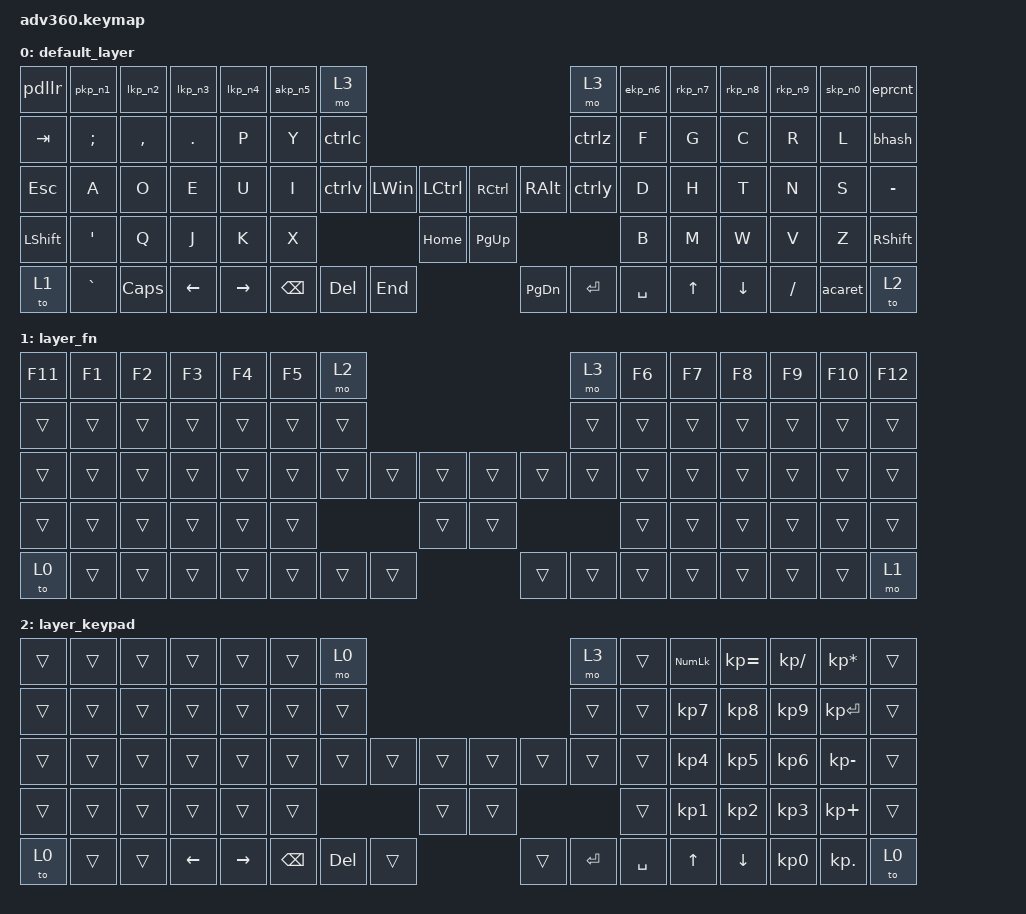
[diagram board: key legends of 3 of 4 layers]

/*
 * Copyright (c) 2020 The ZMK Contributors
 *
 * SPDX-License-Identifier: MIT
 */


/* THIS FILE WAS GENERATED!
 *
 * This file was generated automatically. You may or may not want to
 * edit it directly.
 */

#include <behaviors.dtsi>
#include <dt-bindings/zmk/keys.h>
#include <dt-bindings/zmk/bt.h>
#include <dt-bindings/zmk/rgb.h>
#include <dt-bindings/zmk/backlight.h>

/ {
  behaviors {
    #include "macros.dtsi"

    hm: homerow_mods {
        compatible = "zmk,behavior-hold-tap";
        label = "HOMEROW_MODS";
        #binding-cells = <2>;
        tapping-term-ms = <200>;
        quick_tap_ms = <175>;
        flavor = "tap-preferred";
        bindings = <&kp>, <&kp>;
    };

    pkp_n1: plus_kp_n1 {
        compatible = "zmk,behavior-mod-morph";
        label = "plus_kp_n1";
        #binding-cells = <0>;
        bindings = <&kp PLUS>, <&kp KP_N1>;
        mods = <(MOD_LSFT|MOD_RSFT|MOD_RGUI|MOD_LGUI)>;
    };
    lkp_n2: left_bracket_kp_n2 {
        compatible = "zmk,behavior-mod-morph";
        label = "left_bracket_kp_n2";
        #binding-cells = <0>;
        bindings = <&kp LEFT_BRACKET>, <&kp KP_N2>;
        mods = <(MOD_LSFT|MOD_RSFT|MOD_RGUI|MOD_LGUI)>;
       
    };
    lkp_n3: left_brace_kp_n3 {
        compatible = "zmk,behavior-mod-morph";
        label = "left_brace_kp_n3";
        #binding-cells = <0>;
        bindings = <&kp LEFT_BRACE>, <&kp KP_N3>;
        mods = <(MOD_LSFT|MOD_RSFT|MOD_RGUI|MOD_LGUI)>;
      
    };
    lkp_n4: left_parenthesis_kp_n4 {
        compatible = "zmk,behavior-mod-morph";
        label = "left_parenthesis_kp_n4";
        #binding-cells = <0>;
        bindings = <&kp LEFT_PARENTHESIS>, <&kp KP_N4>;
        mods = <(MOD_LSFT|MOD_RSFT|MOD_RGUI|MOD_LGUI)>;
    };
    akp_n5: amps_kp_n5 {
        compatible = "zmk,behavior-mod-morph";
        label = "amps_kp_n5";
        #binding-cells = <0>;
        bindings = <&kp AMPS>, <&kp KP_N5>;
        mods = <(MOD_LSFT|MOD_RSFT|MOD_RGUI|MOD_LGUI)>;
    };
    ekp_n6: equal_kp_n6 {
        compatible = "zmk,behavior-mod-morph";
        label = "equal_kp_n6";
        #binding-cells = <0>;
        bindings = <&kp EQUAL>, <&kp KP_N6>;
        mods = <(MOD_LSFT|MOD_RSFT|MOD_RGUI|MOD_LGUI)>;
    };
    rkp_n7: right_parenthesis_kp_n7 {
        compatible = "zmk,behavior-mod-morph";
        label = "right_parenthesis_kp_n7";
        #binding-cells = <0>;
        bindings = <&kp RIGHT_PARENTHESIS>, <&kp KP_N7>;
        mods = <(MOD_LSFT|MOD_RSFT|MOD_RGUI|MOD_LGUI)>;
    };
    rkp_n8: right_brace_kp_n8 {
        compatible = "zmk,behavior-mod-morph";
        label = "right_brace_kp_n8";
        #binding-cells = <0>;
        bindings = <&kp RIGHT_BRACE>, <&kp KP_N8>;
        mods = <(MOD_LSFT|MOD_RSFT|MOD_RGUI|MOD_LGUI)>;
    };
    rkp_n9: right_bracket_kp_n9 {
        compatible = "zmk,behavior-mod-morph";
        label = "right_bracket_kp_n9";
        #binding-cells = <0>;
        bindings = <&kp RIGHT_BRACKET>, <&kp KP_N9>;
        mods = <(MOD_LSFT|MOD_RSFT|MOD_RGUI|MOD_LGUI)>;
    };
    skp_n0: star_kp_n0 {
        compatible = "zmk,behavior-mod-morph";
        label = "star_kp_n0";
        #binding-cells = <0>;
        bindings = <&kp STAR>, <&kp KP_N0>;
        mods = <(MOD_LSFT|MOD_RSFT|MOD_RGUI|MOD_LGUI)>;
    };
    eprcnt: excl_prcnt {
        compatible = "zmk,behavior-mod-morph";
        label = "excl_prcnt";
        #binding-cells = <0>;
        bindings = <&kp EXCL>, <&kp PRCNT>;
        mods = <(MOD_LSFT|MOD_RSFT|MOD_RGUI|MOD_LGUI)>;

    };

    pdllr: pipe_dllr {
        compatible = "zmk,behavior-mod-morph";
        label = "pipe_dllr";
        #binding-cells = <0>;
        bindings = <&kp PIPE>, <&kp DLLR>;
        mods = <(MOD_LSFT|MOD_RSFT|MOD_RGUI|MOD_LGUI)>;

    };
    bhash: bslh_hash {
        compatible = "zmk,behavior-mod-morph";
        label = "bslh_hash";
        #binding-cells = <0>;
        bindings = <&kp BSLH>, <&kp HASH>;
        mods = <(MOD_LSFT|MOD_RSFT|MOD_RGUI|MOD_LGUI)>;

    };
    acaret: at_caret {
        compatible = "zmk,behavior-mod-morph";
        label = "at_caret";
        #binding-cells = <0>;
        bindings = <&kp AT>, <&kp CARET>;
        mods = <(MOD_LSFT|MOD_RSFT|MOD_RGUI|MOD_LGUI)>;

    };
  };

    keymap {
        compatible = "zmk,keymap";


        default_layer {
            bindings = <
    &pdllr   &pkp_n1     &lkp_n2         &lkp_n3               &lkp_n4   &akp_n5             &mo 3                                                                                 &mo 3       &ekp_n6  &rkp_n7        &rkp_n8            &rkp_n9      &skp_n0    &eprcnt
   &kp TAB   &kp SEMI    &kp COMMA       &kp PERIOD            &kp P     &kp Y               &ctrlc                                                                                &ctrlz      &kp F    &kp G          &kp C              &kp R        &kp L      &bhash
   &kp ESC   &kp A       &kp O           &kp E                 &kp U     &kp I               &ctrlv                  &kp LEFT_WIN &kp LCTRL  &kp RCTRL  &kp RALT                   &ctrly      &kp D    &kp H          &kp T              &kp N        &kp S      &kp MINUS
   &kp LSHFT &kp APOS    &kp Q           &kp J                 &kp K     &kp X                                                    &kp HOME   &kp PG_UP                                         &kp B    &kp M          &kp W              &kp V        &kp Z      &kp RSHFT
   &to 1     &kp GRAVE   &kp CAPS        &kp LEFT             &kp RIGHT                                &kp BACKSPACE &kp DELETE   &kp END    &kp PG_DN  &kp ENTER   &kp SPACE                           &kp UP         &kp DOWN           &kp SLASH    &acaret    &to 2
            >;
        };

        layer_fn {
            bindings = <
 &kp F11 &kp F1  &kp F2  &kp F3  &kp F4  &kp F5  &mo 2                                                                         &mo 3   &kp F6  &kp F7  &kp F8   &kp F9   &kp F10  &kp F12
 &trans  &trans  &trans  &trans  &trans  &trans  &trans                                                                        &trans  &trans  &trans  &trans   &trans   &trans   &trans
 &trans  &trans  &trans  &trans  &trans  &trans  &trans                 &trans  &trans                  &trans  &trans         &trans  &trans  &trans  &trans   &trans   &trans   &trans
 &trans  &trans  &trans  &trans  &trans  &trans                                 &trans                  &trans                         &trans  &trans  &trans   &trans   &trans   &trans
 &to 0   &trans  &trans  &trans  &trans                          &trans &trans  &trans                  &trans  &trans  &trans                 &trans  &trans   &trans   &trans   &mo 1 
            >;
        };

        layer_keypad {
            bindings = <
  &trans      &trans   &trans  &trans      &trans      &trans   &mo 0                                                                        &mo 3    &trans     &kp KP_NUM    &kp KP_EQUAL   &kp KP_DIVIDE  &kp KP_MULTIPLY   &trans
  &trans      &trans   &trans  &trans      &trans      &trans   &trans                                                                       &trans   &trans     &kp KP_N7     &kp KP_N8      &kp KP_N9      &kp KP_ENTER      &trans
  &trans      &trans   &trans  &trans      &trans      &trans   &trans                    &trans   &trans   &trans   &trans                  &trans   &trans     &kp KP_N4     &kp KP_N5      &kp KP_N6      &kp KP_MINUS      &trans
  &trans      &trans   &trans  &trans      &trans      &trans                                      &trans   &trans                                    &trans     &kp KP_N1     &kp KP_N2      &kp KP_N3      &kp KP_PLUS       &trans
  &to 0       &trans   &trans  &kp LEFT    &kp RIGHT                      &kp BACKSPACE  &kp DEL   &trans   &trans  &kp ENTER  &kp SPACE                         &kp UP        &kp DOWN       &kp KP_N0      &kp KP_DOT        &to 0
            >;       
        };

        layer_mod {
            bindings = <
  &trans         &bt BT_SEL 0   &bt BT_SEL 1   &bt BT_SEL 2   &bt BT_SEL 3   &bt BT_SEL 4  &trans                                                                              &trans      &bt BT_SEL 0        &bt BT_SEL 1   &bt BT_SEL 2            &bt BT_SEL 3   &bt BT_SEL 4   &trans
  &trans         &trans         &trans         &trans         &trans         &trans        &bootloader                                                                         &bootloader &trans              &trans         &trans                  &trans         &trans         &trans
  &trans         &trans         &trans         &trans         &trans         &trans        &trans            &trans &rgb_ug RGB_MEFS_CMD 5  &bt BT_CLR   &trans                &trans      &bt BT_CLR          &bt BT_CLR     &rgb_ug RGB_MEFS_CMD 5  &trans         &trans         &trans
  &trans         &trans         &trans         &trans         &trans         &trans                                 &trans                  &trans                                         &trans              &trans         &trans                  &trans         &trans         &trans
  &trans         &trans         &trans         &bl BL_INC     &bl BL_DEC                           &rgb_ug RGB_TOG  &bl BL_TOG              &bl BL_TOG   &rgb_ug RGB_TOG                                       &bl BL_INC     &bl BL_DEC              &trans         &trans         &trans
            >;
        };

    };
};
